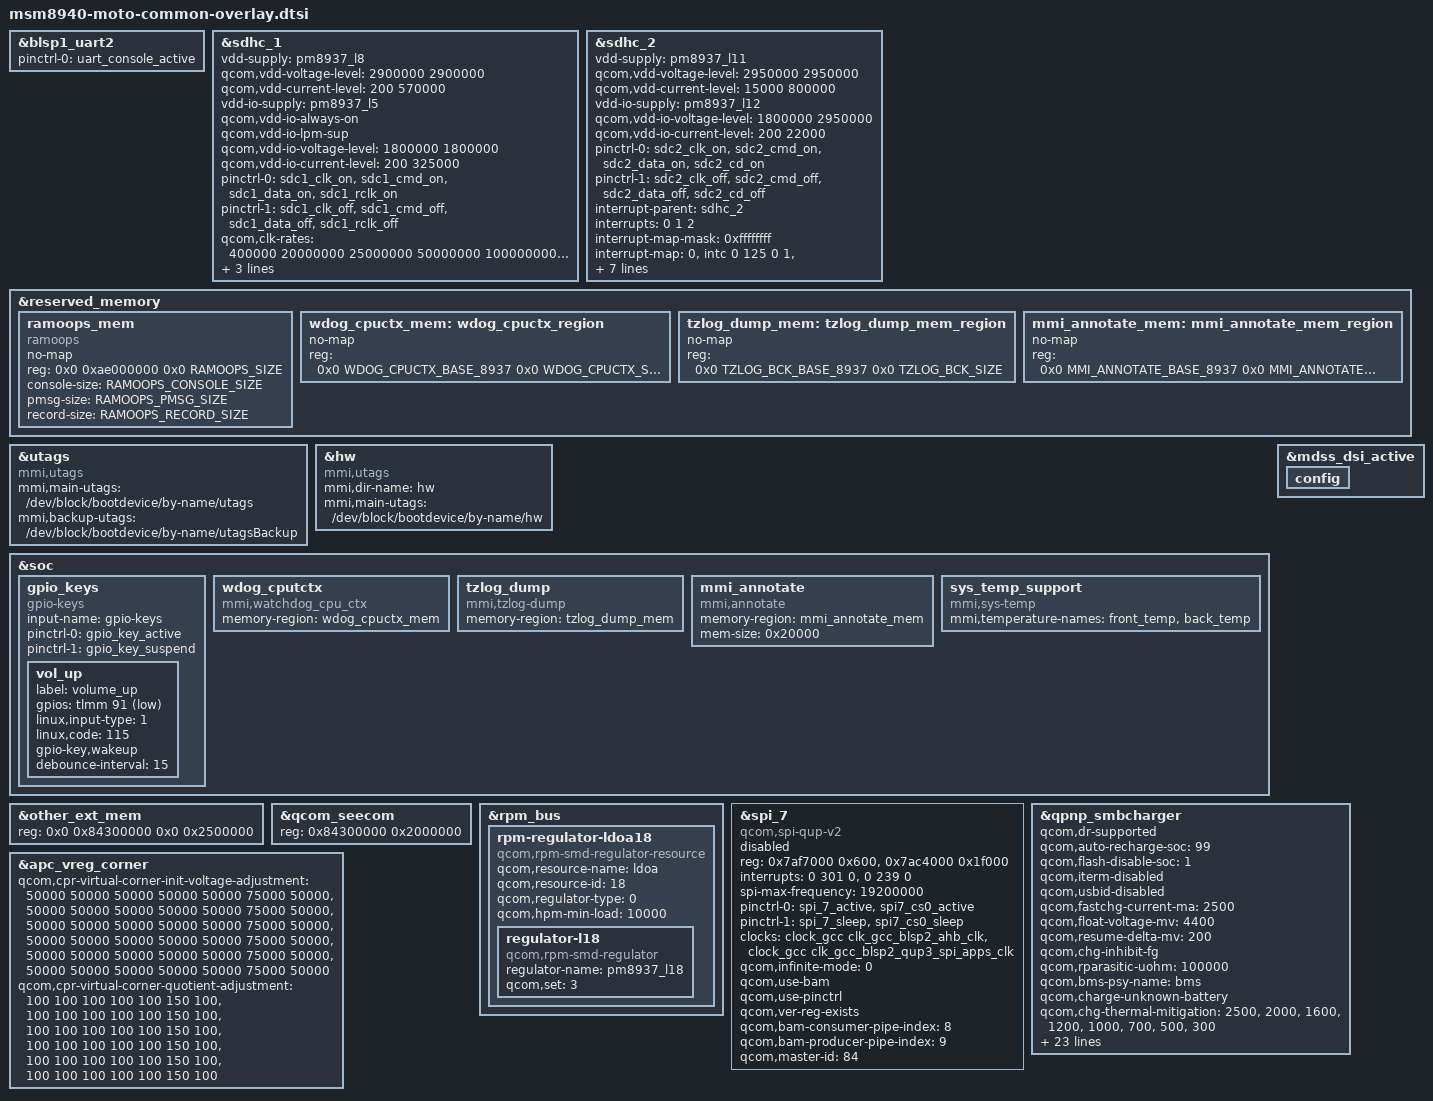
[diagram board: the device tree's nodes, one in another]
/* Copyright (c) 2018, Motorola Mobility Inc. All rights reserved.
 *
 * This program is free software; you can redistribute it and/or modify
 * it under the terms of the GNU General Public License version 2 and
 * only version 2 as published by the Free Software Foundation.
 *
 * This program is distributed in the hope that it will be useful,
 * but WITHOUT ANY WARRANTY; without even the implied warranty of
 * MERCHANTABILITY or FITNESS FOR A PARTICULAR PURPOSE.  See the
 * GNU General Public License for more details.
 */

#include "carrier-channel-ids.dtsi"
#include "msm8937-moto-pinctrl-overlay.dtsi"
#include <dt-bindings/moto/moto-mem-reserve.h>

&blsp1_uart2 {
	status = "ok";
	pinctrl-names = "default";
	pinctrl-0 = <&uart_console_active>;
};

&sdhc_1 {
	/* device core power supply */
	vdd-supply = <&pm8937_l8>;
	qcom,vdd-voltage-level = <2900000 2900000>;
	qcom,vdd-current-level = <200 570000>;

	/* device communication power supply */
	vdd-io-supply = <&pm8937_l5>;
	qcom,vdd-io-always-on;
	qcom,vdd-io-lpm-sup;
	qcom,vdd-io-voltage-level = <1800000 1800000>;
	qcom,vdd-io-current-level = <200 325000>;

	pinctrl-names = "active", "sleep";
	pinctrl-0 = <&sdc1_clk_on &sdc1_cmd_on &sdc1_data_on &sdc1_rclk_on>;
	pinctrl-1 = <&sdc1_clk_off &sdc1_cmd_off &sdc1_data_off &sdc1_rclk_off>;

	qcom,clk-rates = <400000 20000000 25000000 50000000 100000000 192000000
								384000000>;
	qcom,nonremovable;
	qcom,bus-speed-mode = "HS400_1p8v", "HS200_1p8v", "DDR_1p8v";

	status = "ok";
};

&sdhc_2 {
	/* device core power supply */
	vdd-supply = <&pm8937_l11>;
	qcom,vdd-voltage-level = <2950000 2950000>;
	qcom,vdd-current-level = <15000 800000>;

	/* device communication power supply */
	vdd-io-supply = <&pm8937_l12>;
	qcom,vdd-io-voltage-level = <1800000 2950000>;
	qcom,vdd-io-current-level = <200 22000>;

	pinctrl-names = "active", "sleep";
	pinctrl-0 = <&sdc2_clk_on &sdc2_cmd_on &sdc2_data_on &sdc2_cd_on>;
	pinctrl-1 = <&sdc2_clk_off &sdc2_cmd_off &sdc2_data_off &sdc2_cd_off>;

	#address-cells = <0>;
	interrupt-parent = <&sdhc_2>;
	interrupts = <0 1 2>;
	#interrupt-cells = <1>;
	interrupt-map-mask = <0xffffffff>;
	interrupt-map = <0 &intc 0 125 0
		1 &intc 0 221 0
		2 &tlmm 67 0>;
	interrupt-names = "hc_irq", "pwr_irq", "status_irq";
	cd-gpios = <&tlmm 67 0x1>;
	qcom,cd-wakeup;

	qcom,clk-rates = <400000 20000000 25000000 50000000 100000000
								200000000>;
	qcom,bus-speed-mode = "SDR12", "SDR25", "SDR50", "DDR50", "SDR104";

	status = "ok";
};

&reserved_memory {
	ramoops_mem {
		compatible = "ramoops";
		no-map;
		reg = <0x0 0xae000000 0x0 RAMOOPS_SIZE>;
		console-size = <RAMOOPS_CONSOLE_SIZE>;
		pmsg-size = <RAMOOPS_PMSG_SIZE>;
		record-size = <RAMOOPS_RECORD_SIZE>;
	};

	wdog_cpuctx_mem: wdog_cpuctx_region {
		no-map;
		reg = <0x0 WDOG_CPUCTX_BASE_8937
				0x0 WDOG_CPUCTX_SIZE_8937>;
	};

	tzlog_dump_mem: tzlog_dump_mem_region {
		no-map;
		reg = <0x0 TZLOG_BCK_BASE_8937
				0x0 TZLOG_BCK_SIZE>;
	};

	mmi_annotate_mem: mmi_annotate_mem_region {
		no-map;
		reg = <0x0 MMI_ANNOTATE_BASE_8937
				0x0 MMI_ANNOTATE_SIZE>;
	};
};

&utags {
	compatible = "mmi,utags";
	mmi,main-utags = "/dev/block/bootdevice/by-name/utags";
	mmi,backup-utags = "/dev/block/bootdevice/by-name/utagsBackup";
};

&hw {
	compatible = "mmi,utags";
	mmi,dir-name = "hw";
	mmi,main-utags = "/dev/block/bootdevice/by-name/hw";
};

&soc{
	gpio_keys {
		compatible = "gpio-keys";
		input-name = "gpio-keys";
		pinctrl-names = "tlmm_gpio_key_active","tlmm_gpio_key_suspend";
		pinctrl-0 = <&gpio_key_active>;
		pinctrl-1 = <&gpio_key_suspend>;

		vol_up {
			label = "volume_up";
			gpios = <&tlmm 91 0x1>;
			linux,input-type = <1>;
			linux,code = <115>;
			gpio-key,wakeup;
			debounce-interval = <15>;
		};
	};

	wdog_cputctx {
		compatible = "mmi,watchdog_cpu_ctx";
		memory-region = <&wdog_cpuctx_mem>;
	};

	tzlog_dump {
		compatible = "mmi,tzlog-dump";
		memory-region = <&tzlog_dump_mem>;
	};

	mmi_annotate {
		compatible = "mmi,annotate";
		memory-region = <&mmi_annotate_mem>;
		mem-size = <0x20000>;
	};

	sys_temp_support {
		compatible = "mmi,sys-temp";
		mmi,temperature-names = "front_temp",
			"back_temp";
		status = "ok";
    };
};

&mdss_dsi_active {
	config {
		/delete-property/ output-high;
	};
};

&other_ext_mem {
	reg = <0x0 0x84300000 0x0 0x2500000>;
};

&qcom_seecom {
	reg = <0x84300000 0x2000000>;
};

&rpm_bus {
	rpm-regulator-ldoa18 {
		compatible = "qcom,rpm-smd-regulator-resource";
		qcom,resource-name = "ldoa";
		qcom,resource-id = <18>;
		qcom,regulator-type = <0>;
		qcom,hpm-min-load = <10000>;
		status = "okay";

		regulator-l18 {
			compatible = "qcom,rpm-smd-regulator";
			regulator-name = "pm8937_l18";
			qcom,set = <3>;
			status = "okay";
		};
	};
};

&spi_7 { /* BLSP2 QUP2 */
		compatible = "qcom,spi-qup-v2";
		#address-cells = <1>;
		#size-cells = <0>;
		reg-names = "spi_physical", "spi_bam_physical";
		reg = <0x7af7000 0x600>,
		       <0x7ac4000 0x1f000>;
		interrupt-names = "spi_irq", "spi_bam_irq";
		/* IRQ 239 for BLSP2 */
		interrupts = <0 301 0>, <0 239 0>;
		spi-max-frequency = <19200000>;
		pinctrl-names = "spi_default", "spi_sleep";
		pinctrl-0 = <&spi_7_active &spi7_cs0_active>;
		pinctrl-1 = <&spi_7_sleep &spi7_cs0_sleep>;
		clocks = <&clock_gcc clk_gcc_blsp2_ahb_clk>,
			 <&clock_gcc clk_gcc_blsp2_qup3_spi_apps_clk>;
		clock-names = "iface_clk", "core_clk";
		qcom,infinite-mode = <0>;
		qcom,use-bam;
		qcom,use-pinctrl;
		qcom,ver-reg-exists;
		/* need to check pipe index setting*/
		qcom,bam-consumer-pipe-index = <8>;
		qcom,bam-producer-pipe-index = <9>;
		/* master-id for BLSP2 is MSM_BUS_MASTER_BLSP_2 or 84 */
		qcom,master-id = <84>;
		status = "disabled";
	};

&qpnp_smbcharger {
	qcom,dr-supported;
	qcom,auto-recharge-soc = <99>;
	qcom,flash-disable-soc = <1>;
        status = "okay";
	/delete-property/ qcom,iterm-ma;
	qcom,iterm-disabled;
	qcom,usbid-disabled;
	/delete-property/ qcom,autoadjust-vfloat;
	qcom,fastchg-current-ma = <2500>;
	qcom,float-voltage-mv = <4400>;
	qcom,resume-delta-mv = <200>;
	qcom,chg-inhibit-fg;
	qcom,rparasitic-uohm = <100000>;
	qcom,bms-psy-name = "bms";
	qcom,charge-unknown-battery;
	qcom,chg-thermal-mitigation = <2500>, <2000>, <1600>, <1200>, <1000>,
				      <700>, <500>, <300>;
	qcom,dc-thermal-mitigation = <950>, <700>, <600>, <500>, <400>, <300>;
	qcom,parallel-charge-current-map = <2500 2500 0>,
					   <2000 2000 0>,
					   <1600 1600 0>,
					   <1200 1200 0>,
					   <1000 1000 0>,
					   <700 700 0>,
					   <500 500 0>,
					   <300 300 0>;
	qcom,stepchg-voltage-mv = <4200>;
	qcom,stepchg-current-ma = <2500>;
	qcom,stepchg-taper-ma = <2000>;
	qcom,stepchg-iterm-ma = <146>;
	qcom,hot-temp-c = <60>;
	qcom,cold-temp-c = <(-20)>;
	qcom,warm-temp-c = <45>;
	qcom,cool-temp-c = <0>;
	qcom,ext-temp-volt-mv = <4200>;
	qcom,hotspot-thrs-c = <50>;
	qcom,charging-timeout-mins = <0>;
	qcom,precharging-timeout-mins = <0>;
	qcom,bmd-algo-disabled;
	qcom,bmd-pin-src = "bpd_none";
	qcom,usbid-gpio-enabled;
	qcom,force-aicl-rerun;
	qcom,auto-voltage-comp-mv = <150>;
	qcom,enable-hvdcp-9v;
};

&apc_vreg_corner {
	qcom,cpr-virtual-corner-init-voltage-adjustment =
			<50000 50000 50000 50000 50000 75000 50000>,
			<50000 50000 50000 50000 50000 75000 50000>,
			<50000 50000 50000 50000 50000 75000 50000>,
			<50000 50000 50000 50000 50000 75000 50000>,
			<50000 50000 50000 50000 50000 75000 50000>,
			<50000 50000 50000 50000 50000 75000 50000>;

	qcom,cpr-virtual-corner-quotient-adjustment =
			<100 100 100 100 100 150 100>,
			<100 100 100 100 100 150 100>,
			<100 100 100 100 100 150 100>,
			<100 100 100 100 100 150 100>,
			<100 100 100 100 100 150 100>,
			<100 100 100 100 100 150 100>;
};
